# FM33L0XX register map
File version: 1.0
CPU: SC000 r1p0, little endian, no MPU, no FPU, 3 interrupt priority bits
Registers are 32-bit, read-write, reset 0x0 unless marked. A register's access mark holds for its fields unless they carry their own. Offsets are from the block's base; [hi:lo] are bit positions; {n}, {i} and the like mark numbered series.

## GPTIM0 — GENERAL TIMER0 Registers
Base 0x40014400
Same registers: GPTIM1 0x40014800
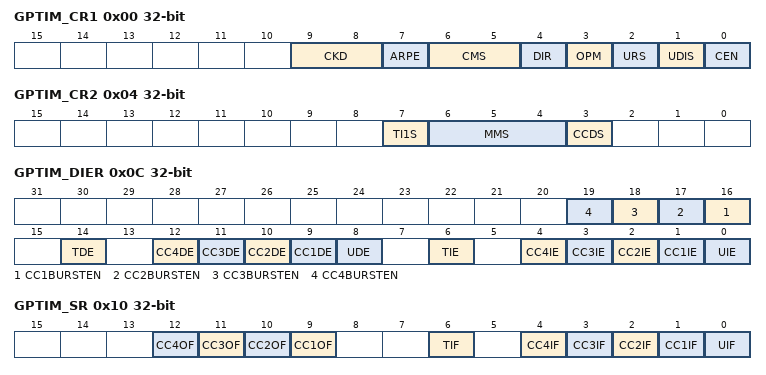
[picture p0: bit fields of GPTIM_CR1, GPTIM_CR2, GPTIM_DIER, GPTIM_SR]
0x00 GPTIM_CR1 — GTIMER CONTROL REGISTER1
  [9:8] CKD — CLK_DIV
    0=tCK_INT; 1=2*tCK_INT; 2=4*tCK_INT
  [7] ARPE — Auto-reload en
    0=DISABLE; 1=ENABLE
  [6:5] CMS — COUNTER ALIGN MODE
    0=edge align mode; 1=center align mode1; 2=center align mode2; 3=center align mode3
  [4] DIR — COUNTER DIR
    0=up; 1=down
  [3] OPM
    0=counter not stop; 1=counter stop
  [2] URS — update request
    0=update by follows; 1=update inly by overflow
  [1] UDIS
    0=DISABLE; 1=ENABLE
  [0] CEN
    0=DISABLE; 1=ENABLE
0x04 GPTIM_CR2 — GTIMER CONTROL REGISTER 2
  [7] TI1S — T1 select
    0=GPTIMx_CH1; 1=XOR (GPTIMx_CH1 XOR CH2 XOR CH3)
  [6:4] MMS — master mode select
    0=UG; 1=CNT_EN; 2=UE; 3=COMPARE PULSE; {v}=OC{v-3}REF (v=4..7)
  [3] CCDS — capture/compare dma select
    0=capture/compare event send dma request; 1=update event send dma request
0x08 GPTIM_SMCR
  [15] ETP
    0=high or rise valid; 1=low or down valid
  [14] ECE — extern clock en
    0=DISABLE; 1=ENABLE
  [13:12] ETPS
    0=NO_DIV; 1=DIV_2; 2=DIV_4; 3=DIV_8
  [11:8] ETF
    0=no filter; 1=fCK_INT; 2=fCK_INT; 3=fCK_INT; 4=fDTS/2; 5=fDTS/2; 6=fDTS/4; 7=fDTS/4; 8=fDTS/8; 9=fDTS/8; 10=fDTS/16; 11=fDTS/16; 12=fDTS/16; 13=fDTS/32; 14=fDTS/32; 15=fDTS/32
  [6:4] TS — trigger select
    {v}=ITR{v} (v=0..3); 4=TI1F_ED; 5=TI1FP1; 6=TI2FP2; 7=ETRF
  [5:4] MSM — master/slave mode
    0=no step; 1=trgi delay
  [2:0] SMS — slave mode select
    0=DISABLE; 1=Encoder1; 2=Encoder2; 3=Encoder3; 4=RESET; 5=GAP; 6=TRIGGER; 7=ETIMER1
0x0C GPTIM_DIER
  [n+15] CC{n}BURSTEN (n=1..4)
    0=SINGLE; 1=BURST
  [14] TDE
    0=DISABLE; 1=ENABLE
  [n+8] CC{n}DE (n=1..4)
    0=DISABLE; 1=ENABLE
  [8] UDE
    0=DISABLE; 1=ENABLE
  [6] TIE
    0=DISABLE; 1=ENABLE
  [n] CC{n}IE (n=1..4)
    0=DISABLE; 1=ENABLE
  [0] UIE — UPDATE IE
    0=DISABLE; 1=ENABLE
0x10 GPTIM_SR
  [all] fields
    0=RESET; 1=SET
  [n+8] CC{n}OF (n=1..4)
  [6] TIF
  [n] CC{n}IF (n=1..4)
  [0] UIF
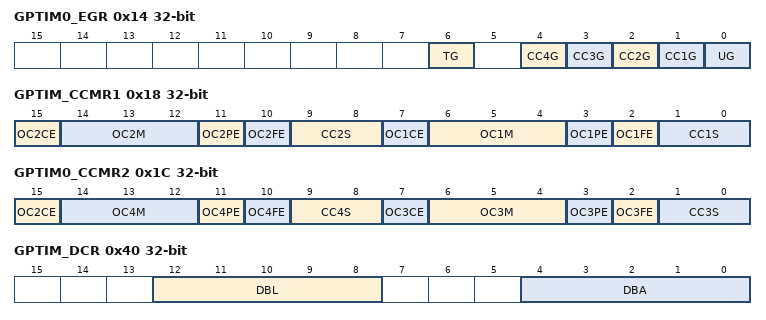
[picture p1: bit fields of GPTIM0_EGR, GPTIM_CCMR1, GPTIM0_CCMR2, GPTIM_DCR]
0x14 GPTIM0_EGR
  [all] fields
    0=RESET; 1=SET
  [6] TG
  [n] CC{n}G (n=1..4)
  [0] UG
0x18 GPTIM_CCMR1
  [15] OC2CE
    0=DISABLE; 1=ENABLE
  [14:12] OC2M — OC2 MODE
    0=CCR2 NOT CONNECT CNT; 1=CCR2=CNT,OC2REF HIGH; 2=CCR2=CNT,OC2REF LOW; 3=CCR2=CNT,OC2REF REVERSE; 4=OC2REF LOW; 5=OC2REF HIGH; 6=PWM1; 7=PWM2
  [11] OC2PE
    0=DISABLE; 1=ENABLE
  [10] OC2FE — OUT COMPARE 2 FAST EN
    0=DISABLE; 1=ENABLE
  [9:8] CC2S — CAPTURE/COMPARE2 SELECT
    0=OUTPUT; 1=INPUT_TI2; 2=INPUT_TI1; 3=INPUT_TRC
  [7] OC1CE
    0=DISABLE; 1=ENABLE
  [6:4] OC1M — OC1 MODE
    0=CCR1 NOT CONNECT CNT; 1=CCR1=CNT,OC1REF HIGH; 2=CCR1=CNT,OC1REF LOW; 3=CCR1=CNT,OC1REF REVERSE; 4=OC1REF LOW; 5=OC1REF HIGH; 6=PWM1; 7=PWM2
  [3] OC1PE
    0=DISABLE; 1=ENABLE
  [2] OC1FE — OUT COMPARE 1 FAST EN
    0=DISABLE; 1=ENABLE
  [1:0] CC1S — CAPTURE/COMPARE1 SELECT
    0=OUTPUT; 1=INPUT_TI1; 2=INPUT_TI2; 3=INPUT_TRC
0x1C GPTIM0_CCMR2
  [15] OC2CE
    0=DISABLE; 1=ENABLE
  [14:12] OC4M — OC4 MODE
    0=CCR4 NOT CONNECT CNT; 1=CCR4=CNT,OC4REF HIGH; 2=CCR4=CNT,OC4REF LOW; 3=CCR4=CNT,OC4REF REVERSE; 4=OC4REF LOW; 5=OC4REF HIGH; 6=PWM1; 7=PWM2
  [11] OC4PE
    0=DISABLE; 1=ENABLE
  [10] OC4FE — OUT COMPARE 4 FAST EN
    0=DISABLE; 1=ENABLE
  [9:8] CC4S — CAPTURE/COMPARE4 SELECT
    0=OUTPUT; 1=INPUT_TI4; 2=INPUT_TI3; 3=INPUT_TRC
  [7] OC3CE
    0=DISABLE; 1=ENABLE
  [6:4] OC3M — OC3 MODE
    0=CCR3 NOT CONNECT CNT; 1=CCR3=CNT,OC3REF HIGH; 2=CCR3=CNT,OC3REF LOW; 3=CCR3=CNT,OC3REF REVERSE; 4=OC3REF LOW; 5=OC3REF HIGH; 6=PWM1; 7=PWM2
  [3] OC3PE
    0=DISABLE; 1=ENABLE
  [2] OC3FE — OUT COMPARE 3 FAST EN
    0=DISABLE; 1=ENABLE
  [1:0] CC3S — CAPTURE/COMPARE3 SELECT
    0=OUTPUT; 1=INPUT_TI3; 2=INPUT_TI4; 3=INPUT_TRC
0x20 GPTIM_CCER
  [13] CC4P
  [4n-4] CC{n}E (n=1..4) — CAPTURE/COMPARE{n} EN
    0=DISABLE; 1=ENABLE
  [8] CC3P
  [5] CC2P
  [1] CC1P
0x24 GPTIM_CNT
  [15:0] CNT — COUNT
0x28 GPTIM_PSC
  [15:0] PSC
0x2C GPTIM_ARR
  [15:0] ARR
{0x30+4i} GPTIM_CCR{i} (i=1..4)
  [15:0] CCR{i}
0x40 GPTIM_DCR
  [12:8] DBL — dma burst length
  [4:0] DBA — dma base adress
0x4C GPTIM_DMAR
  [15:0] DMAR — dma burst register
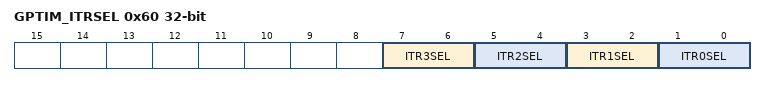
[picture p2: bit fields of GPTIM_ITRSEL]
0x60 GPTIM_ITRSEL
  [7:6] ITR3SEL
    0=COMP1_O; 1=RC4M; 2=COMP2_O; 3=LPTOUT1
  [5:4] ITR2SEL
    0=BSTIM_TRGO; 1=LPUART1_RX; 2=RCLP; 3=XTLF
  [3:2] ITR1SEL
    0=GPTIM1_TRGO; 1=XTHF; 2=RCHF; 3=LPUART0_RX
  [1:0] ITR0SEL
    0=ATIM_TRGO; 1=UART0_RX; 2=UART1_RX; 3=UART4_RX
